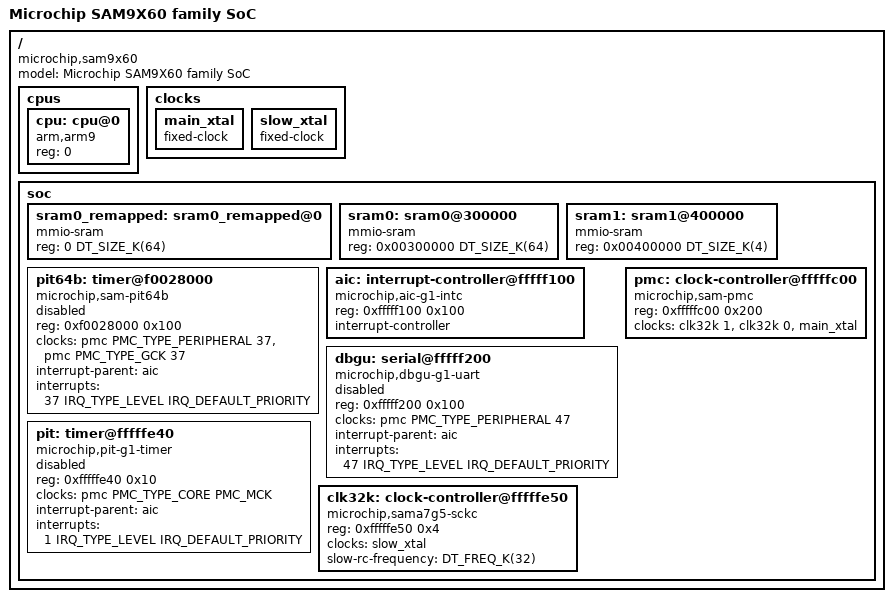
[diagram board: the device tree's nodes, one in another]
/*
 * Copyright (C) 2026 Microchip Technology Inc.
 *
 * SPDX-License-Identifier: Apache-2.0
 *
 */

#include <arm/armv5.dtsi>
#include <mem.h>
#include <zephyr/dt-bindings/clock/microchip_sam_pmc.h>
#include <zephyr/dt-bindings/interrupt-controller/arm-gic.h>

/ {
	model = "Microchip SAM9X60 family SoC";
	compatible = "microchip,sam9x60";

	cpus {
		#address-cells = <1>;
		#size-cells = <0>;

		cpu: cpu@0 {
			device_type = "cpu";
			compatible = "arm,arm9";
			reg = <0>;
		};
	};

	clocks {
		main_xtal: main_xtal {
			compatible = "fixed-clock";
			#clock-cells = <0>;
		};

		slow_xtal: slow_xtal {
			compatible = "fixed-clock";
			#clock-cells = <0>;
		};
	};

	soc {
		sram0_remapped: sram0_remapped@0 {
			compatible = "mmio-sram";
			device_type = "memory";
			reg = <0 DT_SIZE_K(64)>;
		};

		sram0: sram0@300000 {
			compatible = "mmio-sram";
			device_type = "memory";
			reg = <0x00300000 DT_SIZE_K(64)>;
		};

		sram1: sram1@400000 {
			compatible = "mmio-sram";
			device_type = "memory";
			reg = <0x00400000 DT_SIZE_K(4)>;
		};

		pit64b: timer@f0028000 {
			compatible = "microchip,sam-pit64b";
			reg = <0xf0028000 0x100>;
			clocks = <&pmc PMC_TYPE_PERIPHERAL 37>, <&pmc PMC_TYPE_GCK 37>;
			clock-names = "pclk", "gclk";
			interrupt-parent = <&aic>;
			interrupts = <37 IRQ_TYPE_LEVEL IRQ_DEFAULT_PRIORITY>;
			status = "disabled";
		};

		aic: interrupt-controller@fffff100 {
			compatible = "microchip,aic-g1-intc";
			reg = <0xfffff100 0x100>;
			interrupt-controller;
			#interrupt-cells = <3>;
		};

		dbgu: serial@fffff200 {
			compatible = "microchip,dbgu-g1-uart";
			reg = <0xfffff200 0x100>;
			clocks = <&pmc PMC_TYPE_PERIPHERAL 47>;
			interrupt-parent = <&aic>;
			interrupts = <47 IRQ_TYPE_LEVEL IRQ_DEFAULT_PRIORITY>;
			status = "disabled";
		};

		pmc: clock-controller@fffffc00 {
			compatible = "microchip,sam-pmc";
			reg = <0xfffffc00 0x200>;
			#clock-cells = <2>;
			clocks = <&clk32k 1>, <&clk32k 0>, <&main_xtal>;
			clock-names = "td_slck", "md_slck", "main_xtal";
		};

		pit: timer@fffffe40 {
			compatible = "microchip,pit-g1-timer";
			reg = <0xfffffe40 0x10>;
			clocks = <&pmc PMC_TYPE_CORE PMC_MCK>;
			clock-names = "mck";
			interrupt-parent = <&aic>;
			interrupts = <1 IRQ_TYPE_LEVEL IRQ_DEFAULT_PRIORITY>;
			status = "disabled";
		};

		clk32k: clock-controller@fffffe50 {
			compatible = "microchip,sama7g5-sckc";
			reg = <0xfffffe50 0x4>;
			clocks = <&slow_xtal>;
			#clock-cells = <1>;
			slow-rc-frequency = <DT_FREQ_K(32)>;
		};
	};
};
